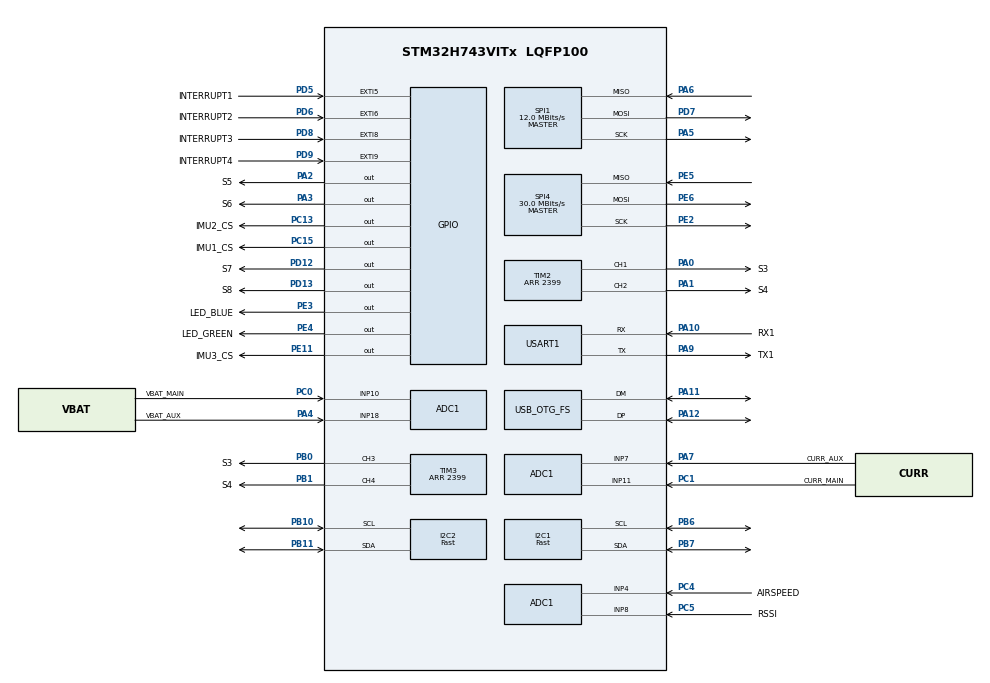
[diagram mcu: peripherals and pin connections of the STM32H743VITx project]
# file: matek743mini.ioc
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ADC1.Channel-0\#ChannelRegularConversion=ADC_CHANNEL_10
ADC1.Channel-1\#ChannelRegularConversion=ADC_CHANNEL_11
ADC1.Channel-2\#ChannelRegularConversion=ADC_CHANNEL_18
ADC1.Channel-3\#ChannelRegularConversion=ADC_CHANNEL_7
ADC1.Channel-4\#ChannelRegularConversion=ADC_CHANNEL_4
ADC1.Channel-5\#ChannelRegularConversion=ADC_CHANNEL_8
ADC1.ContinuousConvMode=ENABLE
ADC1.NbrOfConversion=6
ADC1.NbrOfConversionFlag=1
ADC1.OffsetNumber-0\#ChannelRegularConversion=ADC_OFFSET_NONE
ADC1.OffsetNumber-1\#ChannelRegularConversion=ADC_OFFSET_NONE
ADC1.OffsetNumber-2\#ChannelRegularConversion=ADC_OFFSET_NONE
ADC1.OffsetNumber-3\#ChannelRegularConversion=ADC_OFFSET_NONE
ADC1.OffsetNumber-4\#ChannelRegularConversion=ADC_OFFSET_NONE
ADC1.OffsetNumber-5\#ChannelRegularConversion=ADC_OFFSET_NONE
ADC1.OffsetSignedSaturation-0\#ChannelRegularConversion=DISABLE
ADC1.OffsetSignedSaturation-1\#ChannelRegularConversion=DISABLE
ADC1.OffsetSignedSaturation-2\#ChannelRegularConversion=DISABLE
ADC1.OffsetSignedSaturation-3\#ChannelRegularConversion=DISABLE
ADC1.OffsetSignedSaturation-4\#ChannelRegularConversion=DISABLE
ADC1.OffsetSignedSaturation-5\#ChannelRegularConversion=DISABLE
ADC1.Rank-0\#ChannelRegularConversion=1
ADC1.Rank-1\#ChannelRegularConversion=2
ADC1.Rank-2\#ChannelRegularConversion=3
ADC1.Rank-3\#ChannelRegularConversion=4
ADC1.Rank-4\#ChannelRegularConversion=5
ADC1.Rank-5\#ChannelRegularConversion=6
ADC1.SamplingTime-0\#ChannelRegularConversion=ADC_SAMPLETIME_387CYCLES_5
ADC1.SamplingTime-1\#ChannelRegularConversion=ADC_SAMPLETIME_387CYCLES_5
ADC1.SamplingTime-2\#ChannelRegularConversion=ADC_SAMPLETIME_387CYCLES_5
ADC1.SamplingTime-3\#ChannelRegularConversion=ADC_SAMPLETIME_387CYCLES_5
ADC1.SamplingTime-4\#ChannelRegularConversion=ADC_SAMPLETIME_387CYCLES_5
ADC1.SamplingTime-5\#ChannelRegularConversion=ADC_SAMPLETIME_387CYCLES_5
ADC1.master=1
CORTEX_M7.default_mode_Activation=1
Dma.ADC1.0.Direction=DMA_PERIPH_TO_MEMORY
Dma.ADC1.0.EventEnable=DISABLE
Dma.ADC1.0.FIFOMode=DMA_FIFOMODE_DISABLE
Dma.ADC1.0.Instance=DMA1_Stream0
Dma.ADC1.0.MemDataAlignment=DMA_MDATAALIGN_HALFWORD
Dma.ADC1.0.MemInc=DMA_MINC_ENABLE
Dma.ADC1.0.Mode=DMA_CIRCULAR
Dma.ADC1.0.PeriphDataAlignment=DMA_PDATAALIGN_HALFWORD
Dma.ADC1.0.PeriphInc=DMA_PINC_DISABLE
Dma.ADC1.0.Polarity=HAL_DMAMUX_REQ_GEN_RISING
Dma.ADC1.0.Priority=DMA_PRIORITY_LOW
Dma.ADC1.0.RequestNumber=1
Dma.ADC1.0.SignalID=NONE
Dma.ADC1.0.SyncEnable=DISABLE
Dma.ADC1.0.SyncPolarity=HAL_DMAMUX_SYNC_NO_EVENT
Dma.ADC1.0.SyncRequestNumber=1
Dma.ADC1.0.SyncSignalID=NONE
Dma.Request0=ADC1
Dma.Request1=USART1_TX
Dma.Request2=USART1_RX
Dma.USART1_RX.2.Direction=DMA_PERIPH_TO_MEMORY
Dma.USART1_RX.2.EventEnable=DISABLE
Dma.USART1_RX.2.FIFOMode=DMA_FIFOMODE_DISABLE
Dma.USART1_RX.2.Instance=DMA1_Stream2
Dma.USART1_RX.2.MemDataAlignment=DMA_MDATAALIGN_BYTE
Dma.USART1_RX.2.MemInc=DMA_MINC_ENABLE
Dma.USART1_RX.2.Mode=DMA_CIRCULAR
Dma.USART1_RX.2.PeriphDataAlignment=DMA_PDATAALIGN_BYTE
Dma.USART1_RX.2.PeriphInc=DMA_PINC_DISABLE
Dma.USART1_RX.2.Polarity=HAL_DMAMUX_REQ_GEN_RISING
Dma.USART1_RX.2.Priority=DMA_PRIORITY_LOW
Dma.USART1_RX.2.RequestNumber=1
Dma.USART1_RX.2.SignalID=NONE
Dma.USART1_RX.2.SyncEnable=DISABLE
Dma.USART1_RX.2.SyncPolarity=HAL_DMAMUX_SYNC_NO_EVENT
Dma.USART1_RX.2.SyncRequestNumber=1
Dma.USART1_RX.2.SyncSignalID=NONE
Dma.USART1_TX.1.Direction=DMA_MEMORY_TO_PERIPH
Dma.USART1_TX.1.EventEnable=DISABLE
Dma.USART1_TX.1.FIFOMode=DMA_FIFOMODE_DISABLE
Dma.USART1_TX.1.Instance=DMA1_Stream1
Dma.USART1_TX.1.MemDataAlignment=DMA_MDATAALIGN_BYTE
Dma.USART1_TX.1.MemInc=DMA_MINC_ENABLE
Dma.USART1_TX.1.Mode=DMA_NORMAL
Dma.USART1_TX.1.PeriphDataAlignment=DMA_PDATAALIGN_BYTE
Dma.USART1_TX.1.PeriphInc=DMA_PINC_DISABLE
Dma.USART1_TX.1.Polarity=HAL_DMAMUX_REQ_GEN_RISING
Dma.USART1_TX.1.Priority=DMA_PRIORITY_LOW
Dma.USART1_TX.1.RequestNumber=1
Dma.USART1_TX.1.SignalID=NONE
Dma.USART1_TX.1.SyncEnable=DISABLE
Dma.USART1_TX.1.SyncPolarity=HAL_DMAMUX_SYNC_NO_EVENT
Dma.USART1_TX.1.SyncRequestNumber=1
Dma.USART1_TX.1.SyncSignalID=NONE
FREERTOS.Tasks01=MainTask,24,128,StartDefaultTask,Default,NULL,Dynamic,NULL,NULL
I2C1.I2C_Speed_Mode=I2C_Fast
I2C1.Timing=0x00B03FDB
I2C2.I2C_Speed_Mode=I2C_Fast
I2C2.Timing=0x00B03FDB
Mcu.Family=STM32H7
Mcu.Name=STM32H743VITx
Mcu.Package=LQFP100
NVIC.DMA1_Stream0_IRQn=true\:5\:0\:false\:false\:true\:true\:false\:true\:true
NVIC.DMA1_Stream1_IRQn=true\:5\:0\:false\:false\:true\:true\:false\:true\:true
NVIC.DMA1_Stream2_IRQn=true\:5\:0\:false\:false\:true\:true\:false\:true\:true
NVIC.EXTI9_5_IRQn=true\:5\:0\:false\:false\:true\:true\:true\:true\:true
NVIC.OTG_FS_IRQn=true\:5\:0\:false\:false\:true\:true\:false\:true\:true
NVIC.PriorityGroup=NVIC_PRIORITYGROUP_4
NVIC.TIM7_IRQn=true\:15\:0\:false\:false\:true\:false\:false\:true\:true
NVIC.TimeBase=TIM7_IRQn
NVIC.TimeBaseIP=TIM7
NVIC.USART1_IRQn=true\:5\:0\:false\:false\:true\:true\:false\:true\:true
PA0.GPIO_Label=S3
PA0.Signal=S_TIM2_CH1_ETR
PA1.GPIO_Label=S4
PA1.Signal=S_TIM2_CH2
PA10.GPIO_Label=RX1
PA10.Mode=Asynchronous
PA10.Signal=USART1_RX
PA11.Mode=Device_Only
PA11.Signal=USB_OTG_FS_DM
PA12.Mode=Device_Only
PA12.Signal=USB_OTG_FS_DP
PA2.GPIO_Label=S5
PA2.Signal=GPIO_Output
PA3.GPIO_Label=S6
PA3.Signal=GPIO_Output
PA4.GPIO_Label=VBAT_AUX
PA4.Signal=ADCx_INP18
PA5.Mode=Full_Duplex_Master
PA5.Signal=SPI1_SCK
PA6.Mode=Full_Duplex_Master
PA6.Signal=SPI1_MISO
PA7.GPIO_Label=CURR_AUX
PA7.Signal=ADCx_INP7
PA9.GPIO_Label=TX1
PA9.Mode=Asynchronous
PA9.Signal=USART1_TX
PB0.GPIO_Label=S3
PB0.Signal=S_TIM3_CH3
PB1.GPIO_Label=S4
PB1.Signal=S_TIM3_CH4
PB6.Mode=I2C
PB6.Signal=I2C1_SCL
PB7.Mode=I2C
PB7.Signal=I2C1_SDA
PB10.Mode=I2C
PB10.Signal=I2C2_SCL
PB11.Mode=I2C
PB11.Signal=I2C2_SDA
PC0.GPIO_Label=VBAT_MAIN
PC0.Signal=ADCx_INP10
PC1.GPIO_Label=CURR_MAIN
PC1.Signal=ADCx_INP11
PC13.GPIO_Label=IMU2_CS
PC13.Signal=GPIO_Output
PC15-OSC32_OUT\ (OSC32_OUT).GPIO_Label=IMU1_CS
PC15-OSC32_OUT\ (OSC32_OUT).Signal=GPIO_Output
PC4.GPIO_Label=AIRSPEED
PC4.Signal=ADCx_INP4
PC5.GPIO_Label=RSSI
PC5.Signal=ADCx_INP8
PD12.GPIO_Label=S7
PD12.Signal=GPIO_Output
PD13.GPIO_Label=S8
PD13.Signal=GPIO_Output
PD5.GPIO_Label=INTERRUPT1
PD5.GPIO_ModeDefaultEXTI=GPIO_MODE_IT_RISING_FALLING
PD5.Signal=GPXTI5
PD6.GPIO_Label=INTERRUPT2
PD6.GPIO_ModeDefaultEXTI=GPIO_MODE_IT_RISING_FALLING
PD6.Signal=GPXTI6
PD7.Mode=Full_Duplex_Master
PD7.Signal=SPI1_MOSI
PD8.GPIO_Label=INTERRUPT3
PD8.GPIO_ModeDefaultEXTI=GPIO_MODE_IT_RISING_FALLING
PD8.Signal=GPXTI8
PD9.GPIO_Label=INTERRUPT4
PD9.GPIO_ModeDefaultEXTI=GPIO_MODE_IT_RISING_FALLING
PD9.GPIO_PuPd=GPIO_NOPULL
PD9.Signal=GPXTI9
PE11.GPIO_Label=IMU3_CS
PE11.Signal=GPIO_Output
PE2.Mode=Full_Duplex_Master
PE2.Signal=SPI4_SCK
PE3.GPIO_Label=LED_BLUE
PE3.Signal=GPIO_Output
PE4.GPIO_Label=LED_GREEN
PE4.Signal=GPIO_Output
PE5.Mode=Full_Duplex_Master
PE5.Signal=SPI4_MISO
PE6.Mode=Full_Duplex_Master
PE6.Signal=SPI4_MOSI
PH0-OSC_IN\ (PH0).Mode=HSE-External-Oscillator
PH0-OSC_IN\ (PH0).Signal=RCC_OSC_IN
PH1-OSC_OUT\ (PH1).Mode=HSE-External-Oscillator
PH1-OSC_OUT\ (PH1).Signal=RCC_OSC_OUT
ProjectManager.HeapSize=0x200
ProjectManager.StackSize=0x400
ProjectManager.TargetToolchain=Makefile
RCC.ADCFreq_Value=76000000
RCC.APB1Freq_Value=120000000
RCC.APB2Freq_Value=120000000
RCC.APB3Freq_Value=120000000
RCC.APB4Freq_Value=120000000
RCC.CortexFreq_Value=480000000
RCC.D1PPRE=RCC_APB3_DIV2
RCC.D2PPRE1=RCC_APB1_DIV2
RCC.D2PPRE2=RCC_APB2_DIV2
RCC.D3PPRE=RCC_APB4_DIV2
RCC.DIVM1=1
RCC.DIVM2=1
RCC.DIVM3=1
RCC.DIVN1=120
RCC.DIVN2=19
RCC.DIVN3=19
RCC.DIVQ1=5
RCC.DIVQ3=3
RCC.HCLKFreq_Value=240000000
RCC.HPRE=RCC_HCLK_DIV2
RCC.HSE_VALUE=8000000
RCC.PLL2FRACN=0
RCC.PLL3FRACN=0
RCC.PLLFRACN=0
RCC.PLLSourceVirtual=RCC_PLLSOURCE_HSE
RCC.PWR_Regulator_Voltage_Scale=PWR_REGULATOR_VOLTAGE_SCALE0
RCC.SYSCLKFreq_VALUE=480000000
RCC.SYSCLKSource=RCC_SYSCLKSOURCE_PLLCLK
RCC.USBCLockSelection=RCC_USBCLKSOURCE_HSI48
RCC.USBFreq_Value=48000000
SH.ADCx_INP10.0=ADC1_INP10,IN10-Single-Ended
SH.ADCx_INP11.0=ADC1_INP11,IN11-Single-Ended
SH.ADCx_INP18.0=ADC1_INP18,IN18-Single-Ended
SH.ADCx_INP4.0=ADC1_INP4,IN4-Single-Ended
SH.ADCx_INP7.0=ADC1_INP7,IN7-Single-Ended
SH.ADCx_INP8.0=ADC1_INP8,IN8-Single-Ended
SH.S_TIM2_CH1_ETR.0=TIM2_CH1,PWM Generation1 CH1
SH.S_TIM2_CH2.0=TIM2_CH2,PWM Generation2 CH2
SH.S_TIM3_CH3.0=TIM3_CH3,PWM Generation3 CH3
SH.S_TIM3_CH4.0=TIM3_CH4,PWM Generation4 CH4
SPI1.BaudRatePrescaler=SPI_BAUDRATEPRESCALER_16
SPI1.CalculateBaudRate=12.0 MBits/s
SPI1.DataSize=SPI_DATASIZE_8BIT
SPI1.Direction=SPI_DIRECTION_2LINES
SPI1.Mode=SPI_MODE_MASTER
SPI1.VirtualType=VM_MASTER
SPI4.BaudRatePrescaler=SPI_BAUDRATEPRESCALER_4
SPI4.CalculateBaudRate=30.0 MBits/s
SPI4.DataSize=SPI_DATASIZE_8BIT
SPI4.Direction=SPI_DIRECTION_2LINES
SPI4.Mode=SPI_MODE_MASTER
SPI4.VirtualType=VM_MASTER
TIM2.AutoReloadPreload=TIM_AUTORELOAD_PRELOAD_ENABLE
TIM2.Channel-PWM\ Generation1\ CH1=TIM_CHANNEL_1
TIM2.Channel-PWM\ Generation2\ CH2=TIM_CHANNEL_2
TIM2.Period=2399
TIM3.Channel-PWM\ Generation3\ CH3=TIM_CHANNEL_3
TIM3.Channel-PWM\ Generation4\ CH4=TIM_CHANNEL_4
TIM3.Period=2399
USART1.VirtualMode-Asynchronous=VM_ASYNC
USB_DEVICE.CLASS_NAME_FS=CDC
USB_DEVICE.VirtualMode-CDC_FS=Cdc
USB_DEVICE.VirtualModeFS=Cdc_FS
USB_OTG_FS.VirtualMode=Device_Only
VP_FREERTOS_VS_CMSIS_V2.Mode=CMSIS_V2
VP_MEMORYMAP_VS_MEMORYMAP.Mode=CurAppReg
VP_SYS_VS_tim7.Mode=TIM7
VP_USB_DEVICE_VS_USB_DEVICE_CDC_FS.Mode=CDC_FS
board=custom

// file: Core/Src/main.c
/* USER CODE BEGIN Header */
/**
  ******************************************************************************
  * @file           : main.c
  * @brief          : Main program body
  ******************************************************************************
  * @attention
  *
  * Copyright (c) 2026 STMicroelectronics.
  * All rights reserved.
  *
  * This software is licensed under terms that can be found in the LICENSE file
  * in the root directory of this software component.
  * If no LICENSE file comes with this software, it is provided AS-IS.
  *
  ******************************************************************************
  */
/* USER CODE END Header */
#include "main.h"
#include "FreeRTOS.h"
#include "cmsis_os2.h"
#include "usb_device.h"

ADC_HandleTypeDef hadc1;
DMA_HandleTypeDef hdma_adc1;

I2C_HandleTypeDef hi2c1;
I2C_HandleTypeDef hi2c2;

SPI_HandleTypeDef hspi1;
SPI_HandleTypeDef hspi4;

TIM_HandleTypeDef htim2;
TIM_HandleTypeDef htim3;

UART_HandleTypeDef huart1;
DMA_HandleTypeDef hdma_usart1_tx;
DMA_HandleTypeDef hdma_usart1_rx;

/* Definitions for MainTask */
osThreadId_t MainTaskHandle;
const osThreadAttr_t MainTask_attributes = {
  .name = "MainTask",
  .stack_size = 1024 * 4,
  .priority = (osPriority_t) osPriorityNormal,
};
/* Definitions for AppTask */
osThreadId_t AppTaskHandle;
const osThreadAttr_t AppTask_attributes = {
  .name = "AppTask",
  .stack_size = 4096 * 4,
  .priority = (osPriority_t) osPriorityNormal,
};

void SystemClock_Config(void);
static void MPU_Config(void);
static void MX_GPIO_Init(void);
static void MX_DMA_Init(void);
static void MX_ADC1_Init(void);
static void MX_USART1_UART_Init(void);
static void MX_I2C1_Init(void);
static void MX_I2C2_Init(void);
static void MX_SPI1_Init(void);
static void MX_SPI4_Init(void);
static void MX_TIM2_Init(void);
static void MX_TIM3_Init(void);
void StartDefaultTask(void *argument);
void StartAppTask(void *argument);

/* USER CODE BEGIN PFP */
extern void app_main_task(void *argument);

/* USER CODE END PFP */

int main(void)
{

  /* MPU Configuration--------------------------------------------------------*/
  MPU_Config();

  /* MCU Configuration--------------------------------------------------------*/

  /* Reset of all peripherals, Initializes the Flash interface and the Systick. */
  HAL_Init();

  /* Configure the system clock */
  SystemClock_Config();

  /* Initialize all configured peripherals */
  MX_GPIO_Init();
  HAL_GPIO_WritePin(LED_BLUE_GPIO_Port, LED_BLUE_Pin, GPIO_PIN_RESET);
  HAL_GPIO_WritePin(LED_GREEN_GPIO_Port, LED_GREEN_Pin, GPIO_PIN_SET);
  MX_DMA_Init();
  MX_ADC1_Init();
  MX_USART1_UART_Init();
  MX_I2C1_Init();
  MX_I2C2_Init();
  MX_SPI1_Init();
  MX_SPI4_Init();
  MX_TIM2_Init();
  MX_TIM3_Init();

  /* Init scheduler */
  osKernelInitialize();

  /* Create the thread(s) */
  /* creation of MainTask */
  MainTaskHandle = osThreadNew(StartDefaultTask, NULL, &MainTask_attributes);

  /* Start scheduler */
  osKernelStart();

  /* We should never get here as control is now taken by the scheduler */

  /* Infinite loop */
  while (1)
  {

  }
}

void SystemClock_Config(void)
{
  RCC_OscInitTypeDef RCC_OscInitStruct = {0};
  RCC_ClkInitTypeDef RCC_ClkInitStruct = {0};

  /** Supply configuration update enable
  */
  HAL_PWREx_ConfigSupply(PWR_LDO_SUPPLY);

  /** Configure the main internal regulator output voltage
  */
  __HAL_PWR_VOLTAGESCALING_CONFIG(PWR_REGULATOR_VOLTAGE_SCALE0);

  while(!__HAL_PWR_GET_FLAG(PWR_FLAG_VOSRDY)) {}

  /** Initializes the RCC Oscillators according to the specified parameters
  * in the RCC_OscInitTypeDef structure.
  */
  RCC_OscInitStruct.OscillatorType = RCC_OSCILLATORTYPE_HSI48|RCC_OSCILLATORTYPE_HSE;
  RCC_OscInitStruct.HSEState = RCC_HSE_ON;
  RCC_OscInitStruct.HSI48State = RCC_HSI48_ON;
  RCC_OscInitStruct.PLL.PLLState = RCC_PLL_ON;
  RCC_OscInitStruct.PLL.PLLSource = RCC_PLLSOURCE_HSE;
  RCC_OscInitStruct.PLL.PLLM = 1;
  RCC_OscInitStruct.PLL.PLLN = 120;
  RCC_OscInitStruct.PLL.PLLP = 2;
  RCC_OscInitStruct.PLL.PLLQ = 5;
  RCC_OscInitStruct.PLL.PLLR = 2;
  RCC_OscInitStruct.PLL.PLLRGE = RCC_PLL1VCIRANGE_3;
  RCC_OscInitStruct.PLL.PLLVCOSEL = RCC_PLL1VCOWIDE;
  RCC_OscInitStruct.PLL.PLLFRACN = 0;
  if (HAL_RCC_OscConfig(&RCC_OscInitStruct) != HAL_OK)
  {
    Error_Handler();
  }

  /** Initializes the CPU, AHB and APB buses clocks
  */
  RCC_ClkInitStruct.ClockType = RCC_CLOCKTYPE_HCLK|RCC_CLOCKTYPE_SYSCLK
                              |RCC_CLOCKTYPE_PCLK1|RCC_CLOCKTYPE_PCLK2
                              |RCC_CLOCKTYPE_D3PCLK1|RCC_CLOCKTYPE_D1PCLK1;
  RCC_ClkInitStruct.SYSCLKSource = RCC_SYSCLKSOURCE_PLLCLK;
  RCC_ClkInitStruct.SYSCLKDivider = RCC_SYSCLK_DIV1;
  RCC_ClkInitStruct.AHBCLKDivider = RCC_HCLK_DIV2;
  RCC_ClkInitStruct.APB3CLKDivider = RCC_APB3_DIV2;
  RCC_ClkInitStruct.APB1CLKDivider = RCC_APB1_DIV2;
  RCC_ClkInitStruct.APB2CLKDivider = RCC_APB2_DIV2;
  RCC_ClkInitStruct.APB4CLKDivider = RCC_APB4_DIV2;

  if (HAL_RCC_ClockConfig(&RCC_ClkInitStruct, FLASH_LATENCY_4) != HAL_OK)
  {
    Error_Handler();
  }
}

static void MX_ADC1_Init(void)
{

  ADC_MultiModeTypeDef multimode = {0};
  ADC_ChannelConfTypeDef sConfig = {0};

  /** Common config
  */
  hadc1.Instance = ADC1;
  hadc1.Init.ClockPrescaler = ADC_CLOCK_ASYNC_DIV1;
  hadc1.Init.Resolution = ADC_RESOLUTION_16B;
  hadc1.Init.ScanConvMode = ADC_SCAN_ENABLE;
  hadc1.Init.EOCSelection = ADC_EOC_SINGLE_CONV;
  hadc1.Init.LowPowerAutoWait = DISABLE;
  hadc1.Init.ContinuousConvMode = ENABLE;
  hadc1.Init.NbrOfConversion = 6;
  hadc1.Init.DiscontinuousConvMode = DISABLE;
  hadc1.Init.ExternalTrigConv = ADC_SOFTWARE_START;
  hadc1.Init.ExternalTrigConvEdge = ADC_EXTERNALTRIGCONVEDGE_NONE;
  hadc1.Init.ConversionDataManagement = ADC_CONVERSIONDATA_DR;
  hadc1.Init.Overrun = ADC_OVR_DATA_PRESERVED;
  hadc1.Init.LeftBitShift = ADC_LEFTBITSHIFT_NONE;
  hadc1.Init.OversamplingMode = DISABLE;
  hadc1.Init.Oversampling.Ratio = 1;
  if (HAL_ADC_Init(&hadc1) != HAL_OK)
  {
    Error_Handler();
  }

  /** Configure the ADC multi-mode
  */
  multimode.Mode = ADC_MODE_INDEPENDENT;
  if (HAL_ADCEx_MultiModeConfigChannel(&hadc1, &multimode) != HAL_OK)
  {
    Error_Handler();
  }

  /** Configure Regular Channel
  */
  sConfig.Channel = ADC_CHANNEL_10;
  sConfig.Rank = ADC_REGULAR_RANK_1;
  sConfig.SamplingTime = ADC_SAMPLETIME_387CYCLES_5;
  sConfig.SingleDiff = ADC_SINGLE_ENDED;
  sConfig.OffsetNumber = ADC_OFFSET_NONE;
  sConfig.Offset = 0;
  sConfig.OffsetSignedSaturation = DISABLE;
  if (HAL_ADC_ConfigChannel(&hadc1, &sConfig) != HAL_OK)
  {
    Error_Handler();
  }

  /** Configure Regular Channel
  */
  sConfig.Channel = ADC_CHANNEL_11;
  sConfig.Rank = ADC_REGULAR_RANK_2;
  if (HAL_ADC_ConfigChannel(&hadc1, &sConfig) != HAL_OK)
  {
    Error_Handler();
  }

  /** Configure Regular Channel
  */
  sConfig.Channel = ADC_CHANNEL_18;
  sConfig.Rank = ADC_REGULAR_RANK_3;
  if (HAL_ADC_ConfigChannel(&hadc1, &sConfig) != HAL_OK)
  {
    Error_Handler();
  }

  /** Configure Regular Channel
  */
  sConfig.Channel = ADC_CHANNEL_7;
  sConfig.Rank = ADC_REGULAR_RANK_4;
  if (HAL_ADC_ConfigChannel(&hadc1, &sConfig) != HAL_OK)
  {
    Error_Handler();
  }

  /** Configure Regular Channel
  */
  sConfig.Channel = ADC_CHANNEL_4;
  sConfig.Rank = ADC_REGULAR_RANK_5;
  if (HAL_ADC_ConfigChannel(&hadc1, &sConfig) != HAL_OK)
  {
    Error_Handler();
  }

  /** Configure Regular Channel
  */
  sConfig.Channel = ADC_CHANNEL_8;
  sConfig.Rank = ADC_REGULAR_RANK_6;
  if (HAL_ADC_ConfigChannel(&hadc1, &sConfig) != HAL_OK)
  {
    Error_Handler();
  }

}

static void MX_I2C1_Init(void)
{

  hi2c1.Instance = I2C1;
  hi2c1.Init.Timing = 0x00B03FDB;
  hi2c1.Init.OwnAddress1 = 0;
  hi2c1.Init.AddressingMode = I2C_ADDRESSINGMODE_7BIT;
  hi2c1.Init.DualAddressMode = I2C_DUALADDRESS_DISABLE;
  hi2c1.Init.OwnAddress2 = 0;
  hi2c1.Init.OwnAddress2Masks = I2C_OA2_NOMASK;
  hi2c1.Init.GeneralCallMode = I2C_GENERALCALL_DISABLE;
  hi2c1.Init.NoStretchMode = I2C_NOSTRETCH_DISABLE;
  if (HAL_I2C_Init(&hi2c1) != HAL_OK)
  {
    Error_Handler();
  }

  /** Configure Analogue filter
  */
  if (HAL_I2CEx_ConfigAnalogFilter(&hi2c1, I2C_ANALOGFILTER_ENABLE) != HAL_OK)
  {
    Error_Handler();
  }

  /** Configure Digital filter
  */
  if (HAL_I2CEx_ConfigDigitalFilter(&hi2c1, 0) != HAL_OK)
  {
    Error_Handler();
  }

}

static void MX_I2C2_Init(void)
{

  hi2c2.Instance = I2C2;
  hi2c2.Init.Timing = 0x00B03FDB;
  hi2c2.Init.OwnAddress1 = 0;
  hi2c2.Init.AddressingMode = I2C_ADDRESSINGMODE_7BIT;
  hi2c2.Init.DualAddressMode = I2C_DUALADDRESS_DISABLE;
  hi2c2.Init.OwnAddress2 = 0;
  hi2c2.Init.OwnAddress2Masks = I2C_OA2_NOMASK;
  hi2c2.Init.GeneralCallMode = I2C_GENERALCALL_DISABLE;
  hi2c2.Init.NoStretchMode = I2C_NOSTRETCH_DISABLE;
  if (HAL_I2C_Init(&hi2c2) != HAL_OK)
  {
    Error_Handler();
  }

  /** Configure Analogue filter
  */
  if (HAL_I2CEx_ConfigAnalogFilter(&hi2c2, I2C_ANALOGFILTER_ENABLE) != HAL_OK)
  {
    Error_Handler();
  }

  /** Configure Digital filter
  */
  if (HAL_I2CEx_ConfigDigitalFilter(&hi2c2, 0) != HAL_OK)
  {
    Error_Handler();
  }

}

static void MX_SPI1_Init(void)
{

  /* SPI1 parameter configuration*/
  hspi1.Instance = SPI1;
  hspi1.Init.Mode = SPI_MODE_MASTER;
  hspi1.Init.Direction = SPI_DIRECTION_2LINES;
  hspi1.Init.DataSize = SPI_DATASIZE_8BIT;
  hspi1.Init.CLKPolarity = SPI_POLARITY_LOW;
  hspi1.Init.CLKPhase = SPI_PHASE_1EDGE;
  hspi1.Init.NSS = SPI_NSS_SOFT;
  hspi1.Init.BaudRatePrescaler = SPI_BAUDRATEPRESCALER_16;
  hspi1.Init.FirstBit = SPI_FIRSTBIT_MSB;
  hspi1.Init.TIMode = SPI_TIMODE_DISABLE;
  hspi1.Init.CRCCalculation = SPI_CRCCALCULATION_DISABLE;
  hspi1.Init.CRCPolynomial = 0x0;
  hspi1.Init.NSSPMode = SPI_NSS_PULSE_ENABLE;
  hspi1.Init.NSSPolarity = SPI_NSS_POLARITY_LOW;
  hspi1.Init.FifoThreshold = SPI_FIFO_THRESHOLD_01DATA;
  hspi1.Init.TxCRCInitializationPattern = SPI_CRC_INITIALIZATION_ALL_ZERO_PATTERN;
  hspi1.Init.RxCRCInitializationPattern = SPI_CRC_INITIALIZATION_ALL_ZERO_PATTERN;
  hspi1.Init.MasterSSIdleness = SPI_MASTER_SS_IDLENESS_00CYCLE;
  hspi1.Init.MasterInterDataIdleness = SPI_MASTER_INTERDATA_IDLENESS_00CYCLE;
  hspi1.Init.MasterReceiverAutoSusp = SPI_MASTER_RX_AUTOSUSP_DISABLE;
  hspi1.Init.MasterKeepIOState = SPI_MASTER_KEEP_IO_STATE_DISABLE;
  hspi1.Init.IOSwap = SPI_IO_SWAP_DISABLE;
  if (HAL_SPI_Init(&hspi1) != HAL_OK)
  {
    Error_Handler();
  }

}

static void MX_SPI4_Init(void)
{

  /* SPI4 parameter configuration*/
  hspi4.Instance = SPI4;
  hspi4.Init.Mode = SPI_MODE_MASTER;
  hspi4.Init.Direction = SPI_DIRECTION_2LINES;
  hspi4.Init.DataSize = SPI_DATASIZE_8BIT;
  hspi4.Init.CLKPolarity = SPI_POLARITY_LOW;
  hspi4.Init.CLKPhase = SPI_PHASE_1EDGE;
  hspi4.Init.NSS = SPI_NSS_SOFT;
  hspi4.Init.BaudRatePrescaler = SPI_BAUDRATEPRESCALER_4;
  hspi4.Init.FirstBit = SPI_FIRSTBIT_MSB;
  hspi4.Init.TIMode = SPI_TIMODE_DISABLE;
  hspi4.Init.CRCCalculation = SPI_CRCCALCULATION_DISABLE;
  hspi4.Init.CRCPolynomial = 0x0;
  hspi4.Init.NSSPMode = SPI_NSS_PULSE_ENABLE;
  hspi4.Init.NSSPolarity = SPI_NSS_POLARITY_LOW;
  hspi4.Init.FifoThreshold = SPI_FIFO_THRESHOLD_01DATA;
  hspi4.Init.TxCRCInitializationPattern = SPI_CRC_INITIALIZATION_ALL_ZERO_PATTERN;
  hspi4.Init.RxCRCInitializationPattern = SPI_CRC_INITIALIZATION_ALL_ZERO_PATTERN;
  hspi4.Init.MasterSSIdleness = SPI_MASTER_SS_IDLENESS_00CYCLE;
  hspi4.Init.MasterInterDataIdleness = SPI_MASTER_INTERDATA_IDLENESS_00CYCLE;
  hspi4.Init.MasterReceiverAutoSusp = SPI_MASTER_RX_AUTOSUSP_DISABLE;
  hspi4.Init.MasterKeepIOState = SPI_MASTER_KEEP_IO_STATE_DISABLE;
  hspi4.Init.IOSwap = SPI_IO_SWAP_DISABLE;
  if (HAL_SPI_Init(&hspi4) != HAL_OK)
  {
    Error_Handler();
  }

}

static void MX_TIM2_Init(void)
{

  TIM_MasterConfigTypeDef sMasterConfig = {0};
  TIM_OC_InitTypeDef sConfigOC = {0};

  htim2.Instance = TIM2;
  htim2.Init.Prescaler = 0;
  htim2.Init.CounterMode = TIM_COUNTERMODE_UP;
  htim2.Init.Period = 2399;
  htim2.Init.ClockDivision = TIM_CLOCKDIVISION_DIV1;
  htim2.Init.AutoReloadPreload = TIM_AUTORELOAD_PRELOAD_ENABLE;
  if (HAL_TIM_PWM_Init(&htim2) != HAL_OK)
  {
    Error_Handler();
  }
  sMasterConfig.MasterOutputTrigger = TIM_TRGO_RESET;
  sMasterConfig.MasterSlaveMode = TIM_MASTERSLAVEMODE_DISABLE;
  if (HAL_TIMEx_MasterConfigSynchronization(&htim2, &sMasterConfig) != HAL_OK)
  {
    Error_Handler();
  }
  sConfigOC.OCMode = TIM_OCMODE_PWM1;
  sConfigOC.Pulse = 0;
  sConfigOC.OCPolarity = TIM_OCPOLARITY_HIGH;
  sConfigOC.OCFastMode = TIM_OCFAST_DISABLE;
  if (HAL_TIM_PWM_ConfigChannel(&htim2, &sConfigOC, TIM_CHANNEL_1) != HAL_OK)
  {
    Error_Handler();
  }
  if (HAL_TIM_PWM_ConfigChannel(&htim2, &sConfigOC, TIM_CHANNEL_2) != HAL_OK)
  {
    Error_Handler();
  }
  HAL_TIM_MspPostInit(&htim2);

}

static void MX_TIM3_Init(void)
{

  TIM_MasterConfigTypeDef sMasterConfig = {0};
  TIM_OC_InitTypeDef sConfigOC = {0};

  htim3.Instance = TIM3;
  htim3.Init.Prescaler = 0;
  htim3.Init.CounterMode = TIM_COUNTERMODE_UP;
  htim3.Init.Period = 2399;
  htim3.Init.ClockDivision = TIM_CLOCKDIVISION_DIV1;
  htim3.Init.AutoReloadPreload = TIM_AUTORELOAD_PRELOAD_DISABLE;
  if (HAL_TIM_PWM_Init(&htim3) != HAL_OK)
  {
    Error_Handler();
  }
  sMasterConfig.MasterOutputTrigger = TIM_TRGO_RESET;
  sMasterConfig.MasterSlaveMode = TIM_MASTERSLAVEMODE_DISABLE;
  if (HAL_TIMEx_MasterConfigSynchronization(&htim3, &sMasterConfig) != HAL_OK)
  {
    Error_Handler();
  }
  sConfigOC.OCMode = TIM_OCMODE_PWM1;
  sConfigOC.Pulse = 0;
  sConfigOC.OCPolarity = TIM_OCPOLARITY_HIGH;
  sConfigOC.OCFastMode = TIM_OCFAST_DISABLE;
  if (HAL_TIM_PWM_ConfigChannel(&htim3, &sConfigOC, TIM_CHANNEL_3) != HAL_OK)
  {
    Error_Handler();
  }
  if (HAL_TIM_PWM_ConfigChannel(&htim3, &sConfigOC, TIM_CHANNEL_4) != HAL_OK)
  {
    Error_Handler();
  }
  HAL_TIM_MspPostInit(&htim3);

}

static void MX_USART1_UART_Init(void)
{

  huart1.Instance = USART1;
  huart1.Init.BaudRate = 115200;
  huart1.Init.WordLength = UART_WORDLENGTH_8B;
  huart1.Init.StopBits = UART_STOPBITS_1;
  huart1.Init.Parity = UART_PARITY_NONE;
  huart1.Init.Mode = UART_MODE_TX_RX;
  huart1.Init.HwFlowCtl = UART_HWCONTROL_NONE;
  huart1.Init.OverSampling = UART_OVERSAMPLING_16;
  huart1.Init.OneBitSampling = UART_ONE_BIT_SAMPLE_DISABLE;
  huart1.Init.ClockPrescaler = UART_PRESCALER_DIV1;
  huart1.AdvancedInit.AdvFeatureInit = UART_ADVFEATURE_NO_INIT;
  if (HAL_UART_Init(&huart1) != HAL_OK)
  {
    Error_Handler();
  }
  if (HAL_UARTEx_SetTxFifoThreshold(&huart1, UART_TXFIFO_THRESHOLD_1_8) != HAL_OK)
  {
    Error_Handler();
  }
  if (HAL_UARTEx_SetRxFifoThreshold(&huart1, UART_RXFIFO_THRESHOLD_1_8) != HAL_OK)
  {
    Error_Handler();
  }
  if (HAL_UARTEx_DisableFifoMode(&huart1) != HAL_OK)
  {
    Error_Handler();
  }

}

static void MX_DMA_Init(void)
{

  /* DMA controller clock enable */
  __HAL_RCC_DMA1_CLK_ENABLE();

  /* DMA interrupt init */
  /* DMA1_Stream0_IRQn interrupt configuration */
  HAL_NVIC_SetPriority(DMA1_Stream0_IRQn, 5, 0);
  HAL_NVIC_EnableIRQ(DMA1_Stream0_IRQn);
  /* DMA1_Stream1_IRQn interrupt configuration */
  HAL_NVIC_SetPriority(DMA1_Stream1_IRQn, 5, 0);
  HAL_NVIC_EnableIRQ(DMA1_Stream1_IRQn);
  /* DMA1_Stream2_IRQn interrupt configuration */
  HAL_NVIC_SetPriority(DMA1_Stream2_IRQn, 5, 0);
  HAL_NVIC_EnableIRQ(DMA1_Stream2_IRQn);

}

static void MX_GPIO_Init(void)
{
  GPIO_InitTypeDef GPIO_InitStruct = {0};

  /* GPIO Ports Clock Enable */
  __HAL_RCC_GPIOE_CLK_ENABLE();
  __HAL_RCC_GPIOC_CLK_ENABLE();
  __HAL_RCC_GPIOH_CLK_ENABLE();
  __HAL_RCC_GPIOA_CLK_ENABLE();
  __HAL_RCC_GPIOB_CLK_ENABLE();
  __HAL_RCC_GPIOD_CLK_ENABLE();

  /*Configure GPIO pin Output Level */
  HAL_GPIO_WritePin(GPIOE, LED_BLUE_Pin|LED_GREEN_Pin, GPIO_PIN_RESET);

  /*Configure GPIO pin Output Level */
  HAL_GPIO_WritePin(GPIOE, IMU3_CS_Pin, GPIO_PIN_SET);

  /*Configure GPIO pin Output Level */
  HAL_GPIO_WritePin(GPIOC, IMU2_CS_Pin|IMU1_CS_Pin, GPIO_PIN_SET);

  /*Configure GPIO pin Output Level */
  HAL_GPIO_WritePin(GPIOA, S5_Pin|S6_Pin, GPIO_PIN_RESET);

  /*Configure GPIO pin Output Level */
  HAL_GPIO_WritePin(GPIOD, S7_Pin|S8_Pin, GPIO_PIN_RESET);

  /*Configure GPIO pins : LED_BLUE_Pin LED_GREEN_Pin IMU3_CS_Pin */
  GPIO_InitStruct.Pin = LED_BLUE_Pin|LED_GREEN_Pin|IMU3_CS_Pin;
  GPIO_InitStruct.Mode = GPIO_MODE_OUTPUT_PP;
  GPIO_InitStruct.Pull = GPIO_NOPULL;
  GPIO_InitStruct.Speed = GPIO_SPEED_FREQ_LOW;
  HAL_GPIO_Init(GPIOE, &GPIO_InitStruct);

  /*Configure GPIO pins : IMU2_CS_Pin IMU1_CS_Pin */
  GPIO_InitStruct.Pin = IMU2_CS_Pin|IMU1_CS_Pin;
  GPIO_InitStruct.Mode = GPIO_MODE_OUTPUT_PP;
  GPIO_InitStruct.Pull = GPIO_NOPULL;
  GPIO_InitStruct.Speed = GPIO_SPEED_FREQ_LOW;
  HAL_GPIO_Init(GPIOC, &GPIO_InitStruct);

  /*Configure GPIO pins : S5_Pin S6_Pin */
  GPIO_InitStruct.Pin = S5_Pin|S6_Pin;
  GPIO_InitStruct.Mode = GPIO_MODE_OUTPUT_PP;
  GPIO_InitStruct.Pull = GPIO_NOPULL;
  GPIO_InitStruct.Speed = GPIO_SPEED_FREQ_LOW;
  HAL_GPIO_Init(GPIOA, &GPIO_InitStruct);

  /*Configure GPIO pins : INTERRUPT3_Pin INTERRUPT4_Pin INTERRUPT1_Pin INTERRUPT2_Pin */
  GPIO_InitStruct.Pin = INTERRUPT3_Pin|INTERRUPT4_Pin|INTERRUPT1_Pin|INTERRUPT2_Pin;
  GPIO_InitStruct.Mode = GPIO_MODE_IT_RISING_FALLING;
  GPIO_InitStruct.Pull = GPIO_NOPULL;
  HAL_GPIO_Init(GPIOD, &GPIO_InitStruct);

  /*Configure GPIO pins : S7_Pin S8_Pin */
  GPIO_InitStruct.Pin = S7_Pin|S8_Pin;
  GPIO_InitStruct.Mode = GPIO_MODE_OUTPUT_PP;
  GPIO_InitStruct.Pull = GPIO_NOPULL;
  GPIO_InitStruct.Speed = GPIO_SPEED_FREQ_LOW;
  HAL_GPIO_Init(GPIOD, &GPIO_InitStruct);

  /* EXTI interrupt init*/
  HAL_NVIC_SetPriority(INTERRUPT1_EXTI_IRQn, 5, 0);
  HAL_NVIC_EnableIRQ(INTERRUPT1_EXTI_IRQn);

}

void StartDefaultTask(void *argument)
{
  (void)argument;
  /* init code for USB_DEVICE */
  MX_USB_DEVICE_Init();
  /* USER CODE BEGIN 5 */
  HAL_GPIO_WritePin(LED_GREEN_GPIO_Port, LED_GREEN_Pin, GPIO_PIN_RESET);
  osDelay(500);
  AppTaskHandle = osThreadNew(StartAppTask, NULL, &AppTask_attributes);
  osThreadTerminate(osThreadGetId());
  /* USER CODE END 5 */
}

void StartAppTask(void *argument)
{
  (void)argument;
  HAL_GPIO_WritePin(LED_BLUE_GPIO_Port, LED_BLUE_Pin, GPIO_PIN_SET);
  app_main_task(argument);
  osThreadTerminate(osThreadGetId());
}

 /* MPU Configuration */

void MPU_Config(void)
{
  MPU_Region_InitTypeDef MPU_InitStruct = {0};

  /* Disables the MPU */
  HAL_MPU_Disable();

  /** Initializes and configures the Region and the memory to be protected
  */
  MPU_InitStruct.Enable = MPU_REGION_ENABLE;
  MPU_InitStruct.Number = MPU_REGION_NUMBER0;
  MPU_InitStruct.BaseAddress = 0x0;
  MPU_InitStruct.Size = MPU_REGION_SIZE_4GB;
  MPU_InitStruct.SubRegionDisable = 0x87;
  MPU_InitStruct.TypeExtField = MPU_TEX_LEVEL0;
  MPU_InitStruct.AccessPermission = MPU_REGION_NO_ACCESS;
  MPU_InitStruct.DisableExec = MPU_INSTRUCTION_ACCESS_DISABLE;
  MPU_InitStruct.IsShareable = MPU_ACCESS_SHAREABLE;
  MPU_InitStruct.IsCacheable = MPU_ACCESS_NOT_CACHEABLE;
  MPU_InitStruct.IsBufferable = MPU_ACCESS_NOT_BUFFERABLE;

  HAL_MPU_ConfigRegion(&MPU_InitStruct);
  /* Enables the MPU */
  HAL_MPU_Enable(MPU_PRIVILEGED_DEFAULT);

}

void HAL_TIM_PeriodElapsedCallback(TIM_HandleTypeDef *htim)
{
  if (htim->Instance == TIM7)
  {
    HAL_IncTick();
  }
}

void Error_Handler(void)
{
  __disable_irq();
  while (1)
  {
  }
}
